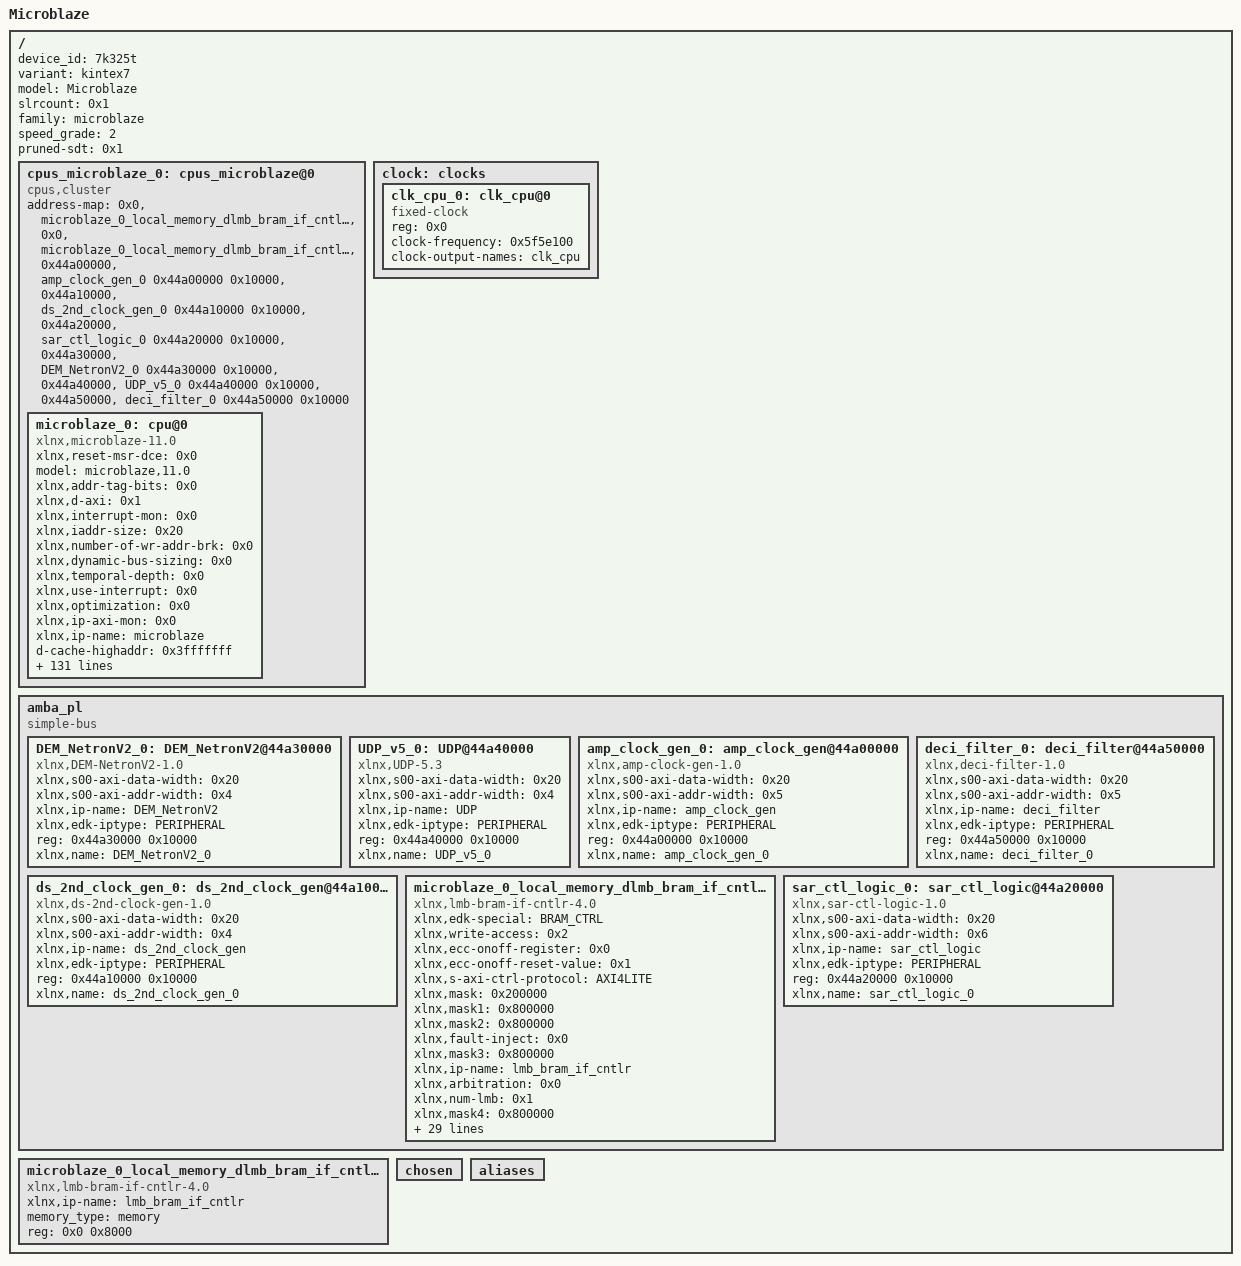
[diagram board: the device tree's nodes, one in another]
/dts-v1/;
/ {
        device_id = "7k325t";
        #address-cells = <0x1>;
        variant = "kintex7";
        model = "Microblaze";
        #size-cells = <0x1>;
        slrcount = <0x1>;
        family = "microblaze";
        speed_grade = "2";
        pruned-sdt = <0x1>;

        cpus_microblaze_0: cpus_microblaze@0 {
                phandle = <0xa>;
                #cpu-mask-cells = <0x1>;
                compatible = "cpus,cluster";
                #address-cells = <0x1>;
                #size-cells = <0x0>;
                address-map = <0x0 &microblaze_0_local_memory_dlmb_bram_if_cntlr_memory 0x0 0x8000>,
                 <0x0 &microblaze_0_local_memory_dlmb_bram_if_cntlr 0x0 0x8000>,
                 <0x44a00000 &amp_clock_gen_0 0x44a00000 0x10000>,
                 <0x44a10000 &ds_2nd_clock_gen_0 0x44a10000 0x10000>,
                 <0x44a20000 &sar_ctl_logic_0 0x44a20000 0x10000>,
                 <0x44a30000 &DEM_NetronV2_0 0x44a30000 0x10000>,
                 <0x44a40000 &UDP_v5_0 0x44a40000 0x10000>,
                 <0x44a50000 &deci_filter_0 0x44a50000 0x10000>;
                #ranges-address-cells = <0x1>;
                #ranges-size-cells = <0x1>;

                microblaze_0: cpu@0 {
                        phandle = <0xb>;
                        xlnx,reset-msr-dce = <0x0>;
                        model = "microblaze,11.0";
                        xlnx,addr-tag-bits = <0x0>;
                        xlnx,d-axi = <0x1>;
                        xlnx,interrupt-mon = <0x0>;
                        xlnx,iaddr-size = <0x20>;
                        xlnx,number-of-wr-addr-brk = <0x0>;
                        xlnx,dynamic-bus-sizing = <0x0>;
                        xlnx,temporal-depth = <0x0>;
                        xlnx,use-interrupt = <0x0>;
                        xlnx,optimization = <0x0>;
                        xlnx,ip-axi-mon = <0x0>;
                        xlnx,ip-name = "microblaze";
                        d-cache-highaddr = <0x3fffffff>;
                        xlnx,dcache-force-tag-lutram = <0x0>;
                        xlnx,pc-width = <0x20>;
                        xlnx,interrupt-is-edge = <0x0>;
                        reg = <0x0>;
                        xlnx,async-interrupt = <0x1>;
                        xlnx,use-mmu = <0x0>;
                        xlnx,reset-msr-ee = <0x0>;
                        xlnx,icache-victims = <0x0>;
                        xlnx,use-reorder-instr = <0x1>;
                        xlnx,d-lmb-mon = <0x0>;
                        xlnx,d-lmb-protocol = <0x0>;
                        xlnx,ill-opcode-exception = <0x0>;
                        xlnx,dcache-always-used = <0x1>;
                        xlnx,use-div = <0x0>;
                        xlnx,dc-axi-mon = <0x0>;
                        xlnx,debug-trace-async-reset = <0x0>;
                        xlnx,trace = <0x0>;
                        xlnx,part = "xc7k325tffg900-2";
                        i-cache-baseaddr = <0x0>;
                        xlnx,use-config-reset = <0x0>;
                        xlnx,pvr = <0x0>;
                        xlnx,i-lmb-mon = <0x0>;
                        xlnx,dcache-byte-size = <0x2000>;
                        xlnx,fault-tolerant = <0x0>;
                        xlnx,family = "kintex7";
                        compatible = "xlnx,microblaze-11.0", "xlnx,microblaze";
                        xlnx,data-size = <0x20>;
                        xlnx,mmu-zones = <0x10>;
                        xlnx,debug-trace-size = <0x2000>;
                        xlnx,mmu-privileged-instr = <0x0>;
                        xlnx,enable-discrete-ports = <0x0>;
                        d-cache-line-size = <0x10>;
                        xlnx,d-lmb = <0x1>;
                        xlnx,sco = <0x0>;
                        xlnx,reset-msr-eip = <0x0>;
                        xlnx,debug-interface = <0x0>;
                        clock-frequency = <0x5f5e100>;
                        xlnx,use-ext-brk = <0x0>;
                        xlnx,daddr-size = <0x20>;
                        xlnx,debug-enabled = <0x1>;
                        xlnx,reset-msr-ice = <0x0>;
                        xlnx,num-sync-ff-dbg-trace-clk = <0x2>;
                        xlnx,i-lmb-protocol = <0x0>;
                        xlnx,endianness = <0x1>;
                        xlnx,fsl-exception = <0x0>;
                        i-cache-line-size = <0x10>;
                        xlnx,use-extended-fsl-instr = <0x0>;
                        xlnx,reset-msr = <0x0>;
                        xlnx,dp-axi-mon = <0x0>;
                        device_type = "cpu";
                        xlnx,branch-target-cache-size = <0x0>;
                        xlnx,dcache-use-writeback = <0x0>;
                        xlnx,div-zero-exception = <0x0>;
                        xlnx,mmu-tlb-access = <0x3>;
                        bus-handle = <&amba_pl>;
                        xlnx,cache-byte-size = <0x2000>;
                        xlnx,pvr-user2 = <0x0>;
                        xlnx,opcode-0x0-illegal = <0x0>;
                        xlnx,icache-line-len = <0x4>;
                        xlnx,ecc-use-ce-exception = <0x0>;
                        xlnx,base-vectors = <0x0>;
                        xlnx,d-lmb-has-prot = <0x0>;
                        xlnx,edk-special = "microblaze";
                        xlnx,use-dcache = <0x0>;
                        xlnx,use-barrel = <0x0>;
                        xlnx,reset-msr-bip = <0x0>;
                        xlnx,allow-dcache-wr = <0x1>;
                        xlnx,debug-external-trace = <0x0>;
                        xlnx,addr-size = <0x20>;
                        xlnx,piaddr-size = <0x20>;
                        i-cache-highaddr = <0x3fffffff>;
                        xlnx,num-sync-ff-clk-debug = <0x2>;
                        xlnx,debug-event-counters = <0x5>;
                        xlnx,fpu-exception = <0x0>;
                        xlnx,allow-icache-wr = <0x1>;
                        xlnx,g-use-exceptions = <0x0>;
                        xlnx,i-axi = <0x0>;
                        xlnx,g-template-list = <0x0>;
                        xlnx,icache-streams = <0x0>;
                        xlnx,dcache-line-len = <0x4>;
                        xlnx,num-sync-ff-clk = <0x2>;
                        xlnx,edk-iptype = "PROCESSOR";
                        xlnx,use-stack-protection = <0x0>;
                        xlnx,use-hw-mul = <0x0>;
                        xlnx,num-sync-ff-dbg-clk = <0x1>;
                        xlnx,interconnect = <0x2>;
                        xlnx,i-lmb-has-prot = <0x0>;
                        xlnx,debug-latency-counters = <0x1>;
                        i-cache-size = <0x2000>;
                        xlnx,exceptions-in-delay-slots = <0x1>;
                        xlnx,use-fpu = <0x0>;
                        xlnx,reset-msr-ie = <0x0>;
                        xlnx,edge-is-positive = <0x1>;
                        xlnx,use-pcmp-instr = <0x0>;
                        xlnx,use-icache = <0x0>;
                        d-cache-size = <0x2000>;
                        xlnx,memory-ip-list = "microblaze_0_local_memory_ilmb_bram_if_cntlr_memory", "microblaze_0_local_memory_dlmb_bram_if_cntlr_memory";
                        xlnx,async-wakeup = <0x3>;
                        xlnx,use-non-secure = <0x0>;
                        xlnx,dcache-addr-tag = <0x0>;
                        xlnx,number-of-rd-addr-brk = <0x0>;
                        d-cache-baseaddr = <0x0>;
                        xlnx,area-optimized = <0x0>;
                        xlnx,avoid-primitives = <0x0>;
                        xlnx,lockstep-slave = <0x0>;
                        xlnx,use-ext-nm-brk = <0x0>;
                        xlnx,instr-size = <0x20>;
                        xlnx,icache-always-used = <0x1>;
                        xlnx,i-lmb = <0x1>;
                        xlnx,mmu-dtlb-size = <0x4>;
                        xlnx,lockstep-select = <0x0>;
                        xlnx,lmb-data-size = <0x20>;
                        xlnx,ic-axi-mon = <0x0>;
                        xlnx,enable-conversion = <0x0>;
                        xlnx,num-sync-ff-clk-irq = <0x1>;
                        xlnx,fsl-links = <0x0>;
                        timebase-frequency = <0x5f5e100>;
                        xlnx,icache-force-tag-lutram = <0x0>;
                        xlnx,dcache-data-width = <0x0>;
                        xlnx,dcache-victims = <0x0>;
                        xlnx,use-branch-target-cache = <0x0>;
                        xlnx,debug-profile-size = <0x0>;
                        xlnx,unaligned-exceptions = <0x0>;
                        xlnx,lockstep-master = <0x0>;
                        xlnx,freq = <0x5f5e100>;
                        xlnx,number-of-pc-brk = <0x1>;
                        xlnx,mmu-itlb-size = <0x2>;
                        xlnx,imprecise-exceptions = <0x0>;
                        xlnx,use-msr-instr = <0x0>;
                        xlnx,icache-data-width = <0x0>;
                        xlnx,debug-counter-width = <0x20>;
                };
        };

        clock: clocks {
                phandle = <0xc>;
                #address-cells = <0x1>;
                #size-cells = <0x0>;

                clk_cpu_0: clk_cpu@0 {
                        phandle = <0xd>;
                        compatible = "fixed-clock";
                        reg = <0x0>;
                        clock-frequency = <0x5f5e100>;
                        clock-output-names = "clk_cpu";
                        #clock-cells = <0x0>;
                };
        };

        amba_pl: amba_pl {
                phandle = <0x9>;
                ranges;
                compatible = "simple-bus";
                #address-cells = <0x1>;
                #size-cells = <0x1>;

                DEM_NetronV2_0: DEM_NetronV2@44a30000 {
                        phandle = <0x6>;
                        xlnx,s00-axi-data-width = <0x20>;
                        compatible = "xlnx,DEM-NetronV2-1.0";
                        status = "okay";
                        xlnx,s00-axi-addr-width = <0x4>;
                        xlnx,ip-name = "DEM_NetronV2";
                        xlnx,edk-iptype = "PERIPHERAL";
                        reg = <0x44a30000 0x10000>;
                        xlnx,name = "DEM_NetronV2_0";
                };

                UDP_v5_0: UDP@44a40000 {
                        phandle = <0x7>;
                        xlnx,s00-axi-data-width = <0x20>;
                        compatible = "xlnx,UDP-5.3";
                        status = "okay";
                        xlnx,s00-axi-addr-width = <0x4>;
                        xlnx,ip-name = "UDP";
                        xlnx,edk-iptype = "PERIPHERAL";
                        reg = <0x44a40000 0x10000>;
                        xlnx,name = "UDP_v5_0";
                };

                amp_clock_gen_0: amp_clock_gen@44a00000 {
                        phandle = <0x3>;
                        xlnx,s00-axi-data-width = <0x20>;
                        compatible = "xlnx,amp-clock-gen-1.0";
                        status = "okay";
                        xlnx,s00-axi-addr-width = <0x5>;
                        xlnx,ip-name = "amp_clock_gen";
                        xlnx,edk-iptype = "PERIPHERAL";
                        reg = <0x44a00000 0x10000>;
                        xlnx,name = "amp_clock_gen_0";
                };

                deci_filter_0: deci_filter@44a50000 {
                        phandle = <0x8>;
                        xlnx,s00-axi-data-width = <0x20>;
                        compatible = "xlnx,deci-filter-1.0";
                        status = "okay";
                        xlnx,s00-axi-addr-width = <0x5>;
                        xlnx,ip-name = "deci_filter";
                        xlnx,edk-iptype = "PERIPHERAL";
                        reg = <0x44a50000 0x10000>;
                        xlnx,name = "deci_filter_0";
                };

                ds_2nd_clock_gen_0: ds_2nd_clock_gen@44a10000 {
                        phandle = <0x4>;
                        xlnx,s00-axi-data-width = <0x20>;
                        compatible = "xlnx,ds-2nd-clock-gen-1.0";
                        status = "okay";
                        xlnx,s00-axi-addr-width = <0x4>;
                        xlnx,ip-name = "ds_2nd_clock_gen";
                        xlnx,edk-iptype = "PERIPHERAL";
                        reg = <0x44a10000 0x10000>;
                        xlnx,name = "ds_2nd_clock_gen_0";
                };

                microblaze_0_local_memory_dlmb_bram_if_cntlr: lmb_bram_if_cntlr@0 {
                        phandle = <0x2>;
                        xlnx,edk-special = "BRAM_CTRL";
                        xlnx,write-access = <0x2>;
                        compatible = "xlnx,lmb-bram-if-cntlr-4.0", "xlnx,axi-bram-ctrl";
                        xlnx,ecc-onoff-register = <0x0>;
                        xlnx,ecc-onoff-reset-value = <0x1>;
                        xlnx,s-axi-ctrl-protocol = "AXI4LITE";
                        xlnx,mask = <0x200000>;
                        xlnx,mask1 = <0x800000>;
                        xlnx,mask2 = <0x800000>;
                        xlnx,fault-inject = <0x0>;
                        xlnx,mask3 = <0x800000>;
                        xlnx,ip-name = "lmb_bram_if_cntlr";
                        xlnx,arbitration = <0x0>;
                        xlnx,num-lmb = <0x1>;
                        xlnx,mask4 = <0x800000>;
                        reg = <0x0 0x8000>;
                        xlnx,s-axi-ctrl-addr-width = <0x20>;
                        xlnx,mask5 = <0x800000>;
                        xlnx,ecc-status-registers = <0x0>;
                        xlnx,prot-cfg = <0xff>;
                        xlnx,mask6 = <0x800000>;
                        xlnx,lmb-protocol = <0x0>;
                        xlnx,ce-counter-width = <0x0>;
                        xlnx,prot-cfg1 = <0xff>;
                        xlnx,mask7 = <0x800000>;
                        xlnx,ecc = <0x0>;
                        xlnx,edk-iptype = "PERIPHERAL";
                        xlnx,prot-cfg2 = <0xff>;
                        xlnx,lmb-dwidth = <0x20>;
                        xlnx,interconnect = <0x0>;
                        xlnx,ce-failing-registers = <0x0>;
                        xlnx,prot-cfg3 = <0xff>;
                        xlnx,ue-failing-registers = <0x0>;
                        xlnx,prot-cfg4 = <0xff>;
                        xlnx,lmb-has-prot = <0x0>;
                        status = "okay";
                        xlnx,data-width = <0x20>;
                        xlnx,prot-cfg5 = <0xff>;
                        xlnx,s-axi-ctrl-data-width = <0x20>;
                        xlnx,prot-cfg6 = <0xff>;
                        xlnx,bram-awidth = <0x20>;
                        xlnx,prot-cfg7 = <0xff>;
                        xlnx,lmb-awidth = <0x20>;
                        xlnx,name = "microblaze_0_local_memory_dlmb_bram_if_cntlr";
                };

                sar_ctl_logic_0: sar_ctl_logic@44a20000 {
                        phandle = <0x5>;
                        xlnx,s00-axi-data-width = <0x20>;
                        compatible = "xlnx,sar-ctl-logic-1.0";
                        status = "okay";
                        xlnx,s00-axi-addr-width = <0x6>;
                        xlnx,ip-name = "sar_ctl_logic";
                        xlnx,edk-iptype = "PERIPHERAL";
                        reg = <0x44a20000 0x10000>;
                        xlnx,name = "sar_ctl_logic_0";
                };
        };

        microblaze_0_local_memory_dlmb_bram_if_cntlr_memory: memory@0 {
                phandle = <0x1>;
                compatible = "xlnx,lmb-bram-if-cntlr-4.0";
                xlnx,ip-name = "lmb_bram_if_cntlr";
                device_type = "memory";
                memory_type = "memory";
                reg = <0x0 0x8000>;
        };

        chosen {
        };

        aliases {
        };

        __symbols__ {
                cpus_microblaze_0 = "/cpus_microblaze@0";
                microblaze_0 = "/cpus_microblaze@0/cpu@0";
                clock = "/clocks";
                clk_cpu_0 = "/clocks/clk_cpu@0";
                amba_pl = "/amba_pl";
                DEM_NetronV2_0 = "/amba_pl/DEM_NetronV2@44a30000";
                UDP_v5_0 = "/amba_pl/UDP@44a40000";
                amp_clock_gen_0 = "/amba_pl/amp_clock_gen@44a00000";
                deci_filter_0 = "/amba_pl/deci_filter@44a50000";
                ds_2nd_clock_gen_0 = "/amba_pl/ds_2nd_clock_gen@44a10000";
                microblaze_0_local_memory_dlmb_bram_if_cntlr = "/amba_pl/lmb_bram_if_cntlr@0";
                sar_ctl_logic_0 = "/amba_pl/sar_ctl_logic@44a20000";
                microblaze_0_local_memory_dlmb_bram_if_cntlr_memory = "/memory@0";
        };
};
